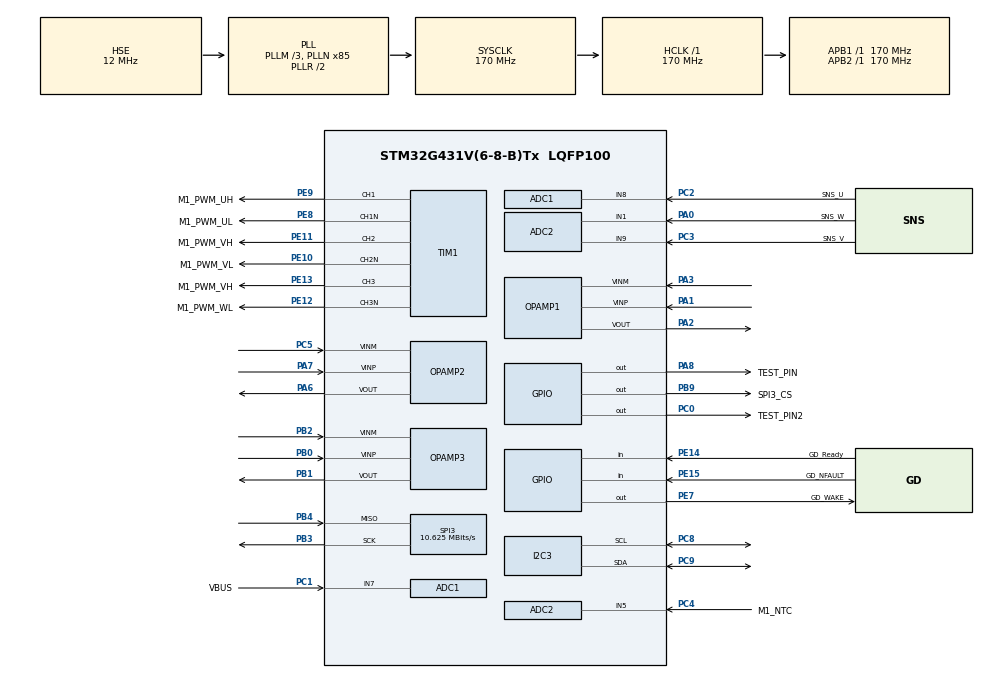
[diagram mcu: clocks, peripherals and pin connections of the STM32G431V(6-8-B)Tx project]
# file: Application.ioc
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ADC1.ClockPrescaler=ADC_CLOCK_ASYNC_DIV4
ADC1.EOCSelection=ADC_EOC_SEQ_CONV
ADC1.EnableInjectedConversion=ENABLE
ADC1.EnableRegularConversion=DISABLE
ADC1.ExternalTrigInjecConv=ADC_EXTERNALTRIGINJEC_T1_TRGO
ADC1.InjNumberOfConversion=4
ADC1.InjectedChannel-1\#ChannelInjectedConversion=ADC_CHANNEL_3
ADC1.InjectedChannel-2\#ChannelInjectedConversion=ADC_CHANNEL_7
ADC1.InjectedChannel-3\#ChannelInjectedConversion=ADC_CHANNEL_12
ADC1.InjectedChannel-4\#ChannelInjectedConversion=ADC_CHANNEL_8
ADC1.InjectedOffsetNumber-1\#ChannelInjectedConversion=ADC_OFFSET_NONE
ADC1.InjectedOffsetNumber-2\#ChannelInjectedConversion=ADC_OFFSET_NONE
ADC1.InjectedOffsetNumber-3\#ChannelInjectedConversion=ADC_OFFSET_NONE
ADC1.InjectedOffsetNumber-4\#ChannelInjectedConversion=ADC_OFFSET_NONE
ADC1.InjectedRank-1\#ChannelInjectedConversion=1
ADC1.InjectedRank-2\#ChannelInjectedConversion=2
ADC1.InjectedRank-3\#ChannelInjectedConversion=3
ADC1.InjectedRank-4\#ChannelInjectedConversion=4
ADC1.InjectedSamplingTime-1\#ChannelInjectedConversion=ADC_SAMPLETIME_6CYCLES_5
ADC1.InjectedSamplingTime-2\#ChannelInjectedConversion=ADC_SAMPLETIME_24CYCLES_5
ADC1.InjectedSamplingTime-3\#ChannelInjectedConversion=ADC_SAMPLETIME_24CYCLES_5
ADC1.InjectedSamplingTime-4\#ChannelInjectedConversion=ADC_SAMPLETIME_24CYCLES_5
ADC1.Rank1_Channel=ADC_CHANNEL_3
ADC1.Rank2_Channel=ADC_CHANNEL_7
ADC1.Rank3_Channel=ADC_CHANNEL_12
ADC1.Rank4_Channel=ADC_CHANNEL_8
ADC1.master=1
ADC2.ClockPrescaler=ADC_CLOCK_ASYNC_DIV4
ADC2.EOCSelection=ADC_EOC_SEQ_CONV
ADC2.EnableInjectedConversion=ENABLE
ADC2.EnableRegularConversion=DISABLE
ADC2.ExternalTrigInjecConv=ADC_EXTERNALTRIGINJEC_T1_TRGO
ADC2.InjNumberOfConversion=4
ADC2.InjectedChannel-1\#ChannelInjectedConversion=ADC_CHANNEL_3
ADC2.InjectedChannel-2\#ChannelInjectedConversion=ADC_CHANNEL_1
ADC2.InjectedChannel-3\#ChannelInjectedConversion=ADC_CHANNEL_5
ADC2.InjectedChannel-4\#ChannelInjectedConversion=ADC_CHANNEL_9
ADC2.InjectedOffsetNumber-1\#ChannelInjectedConversion=ADC_OFFSET_NONE
ADC2.InjectedOffsetNumber-2\#ChannelInjectedConversion=ADC_OFFSET_NONE
ADC2.InjectedOffsetNumber-3\#ChannelInjectedConversion=ADC_OFFSET_NONE
ADC2.InjectedOffsetNumber-4\#ChannelInjectedConversion=ADC_OFFSET_NONE
ADC2.InjectedRank-1\#ChannelInjectedConversion=1
ADC2.InjectedRank-2\#ChannelInjectedConversion=2
ADC2.InjectedRank-3\#ChannelInjectedConversion=3
ADC2.InjectedRank-4\#ChannelInjectedConversion=4
ADC2.InjectedSamplingTime-1\#ChannelInjectedConversion=ADC_SAMPLETIME_6CYCLES_5
ADC2.InjectedSamplingTime-2\#ChannelInjectedConversion=ADC_SAMPLETIME_24CYCLES_5
ADC2.InjectedSamplingTime-3\#ChannelInjectedConversion=ADC_SAMPLETIME_24CYCLES_5
ADC2.InjectedSamplingTime-4\#ChannelInjectedConversion=ADC_SAMPLETIME_24CYCLES_5
ADC2.Rank1_Channel=ADC_CHANNEL_3
ADC2.Rank2_Channel=ADC_CHANNEL_1
ADC2.Rank3_Channel=ADC_CHANNEL_5
ADC2.Rank4_Channel=ADC_CHANNEL_9
FREERTOS.Tasks01=DebugTask,0,128,App_DebugTask,As weak,NULL,Dynamic,NULL,NULL
I2C3.I2C_Fall_Time=100
I2C3.I2C_Rise_Time=100
I2C3.Timing=0x40B285C2
Mcu.Family=STM32G4
Mcu.Name=STM32G431V(6-8-B)Tx
Mcu.Package=LQFP100
Mcu.UserConstants=PWM_PERIOD_CYCLES,8500;TIM_CLOCK_DIVIDER,1;REP_COUNTER,1;DEAD_TIME_COUNTS,170
NVIC.ADC1_2_IRQn=true\:5\:0\:false\:true\:true\:2\:true\:true\:true\:true
NVIC.PriorityGroup=NVIC_PRIORITYGROUP_4
NVIC.TIM1_UP_TIM16_IRQn=true\:5\:0\:false\:true\:true\:1\:true\:true\:true\:true
NVIC.TIM2_IRQn=true\:15\:0\:false\:false\:true\:false\:false\:true\:true
NVIC.TimeBase=TIM2_IRQn
NVIC.TimeBaseIP=TIM2
PA0.GPIO_Label=SNS_W
PA0.Mode=IN1-Single-Ended
PA0.Signal=ADC2_IN1
PA1.Mode=Standalone
PA1.Signal=OPAMP1_VINP
PA13.Mode=Serial_Wire
PA13.Signal=SYS_JTMS-SWDIO
PA14.Mode=Serial_Wire
PA14.Signal=SYS_JTCK-SWCLK
PA2.Signal=SharedAnalog_PA2
PA3.Mode=Standalone
PA3.Signal=OPAMP1_VINM
PA6.Signal=SharedAnalog_PA6
PA7.Mode=Standalone
PA7.Signal=OPAMP2_VINP
PA8.GPIO_Label=TEST_PIN
PA8.GPIO_Speed=GPIO_SPEED_FREQ_VERY_HIGH
PA8.Signal=GPIO_Output
PB0.Mode=Standalone
PB0.Signal=OPAMP3_VINP
PB1.Signal=SharedAnalog_PB1
PB2.Mode=Standalone
PB2.Signal=OPAMP3_VINM
PB3.GPIO_Speed=GPIO_SPEED_FREQ_VERY_HIGH
PB3.Mode=RX_Only_Simplex_Unidirect_Master
PB3.Signal=SPI3_SCK
PB4.GPIO_Speed=GPIO_SPEED_FREQ_VERY_HIGH
PB4.Mode=RX_Only_Simplex_Unidirect_Master
PB4.Signal=SPI3_MISO
PB5.Signal=SPI3_MOSI
PB9.GPIO_FM9=SYSCFG_FASTMODEPLUS_PB9
PB9.GPIO_Label=SPI3_CS
PB9.GPIO_PuPd=GPIO_PULLUP
PB9.GPIO_Speed=GPIO_SPEED_FREQ_VERY_HIGH
PB9.PinState=GPIO_PIN_SET
PB9.Signal=GPIO_Output
PC0.GPIO_Label=TEST_PIN2
PC0.GPIO_Speed=GPIO_SPEED_FREQ_VERY_HIGH
PC0.Signal=GPIO_Output
PC1.GPIO_Label=VBUS
PC1.Mode=IN7-Single-Ended
PC1.Signal=ADC1_IN7
PC2.GPIO_Label=SNS_U
PC2.Mode=IN8-Single-Ended
PC2.Signal=ADC1_IN8
PC3.GPIO_Label=SNS_V
PC3.Mode=IN9-Single-Ended
PC3.Signal=ADC2_IN9
PC4.GPIO_Label=M1_NTC
PC4.Mode=IN5-Single-Ended
PC4.Signal=ADC2_IN5
PC5.Mode=Standalone
PC5.Signal=OPAMP2_VINM
PC8.Mode=I2C
PC8.Signal=I2C3_SCL
PC9.Mode=I2C
PC9.Signal=I2C3_SDA
PE10.GPIO_Label=M1_PWM_VL
PE10.GPIO_PuPd=GPIO_PULLDOWN
PE10.GPIO_Speed=GPIO_SPEED_FREQ_HIGH
PE10.Mode=PWM Generation2 CH2 CH2N
PE10.Signal=TIM1_CH2N
PE11.GPIO_Label=M1_PWM_VH
PE11.GPIO_PuPd=GPIO_PULLDOWN
PE11.GPIO_Speed=GPIO_SPEED_FREQ_HIGH
PE11.Signal=S_TIM1_CH2
PE12.GPIO_Label=M1_PWM_WL
PE12.GPIO_PuPd=GPIO_PULLDOWN
PE12.GPIO_Speed=GPIO_SPEED_FREQ_HIGH
PE12.Mode=PWM Generation3 CH3 CH3N
PE12.Signal=TIM1_CH3N
PE13.GPIO_Label=M1_PWM_VH
PE13.GPIO_PuPd=GPIO_PULLDOWN
PE13.GPIO_Speed=GPIO_SPEED_FREQ_HIGH
PE13.Signal=S_TIM1_CH3
PE14.GPIO_Label=GD_Ready
PE14.Signal=GPIO_Input
PE15.GPIO_Label=GD_NFAULT
PE15.Signal=GPIO_Input
PE7.GPIO_Label=GD_WAKE
PE7.Signal=GPIO_Output
PE8.GPIO_Label=M1_PWM_UL
PE8.GPIO_PuPd=GPIO_PULLDOWN
PE8.GPIO_Speed=GPIO_SPEED_FREQ_HIGH
PE8.Mode=PWM Generation1 CH1 CH1N
PE8.Signal=TIM1_CH1N
PE9.GPIO_Label=M1_PWM_UH
PE9.GPIO_PuPd=GPIO_PULLDOWN
PE9.GPIO_Speed=GPIO_SPEED_FREQ_HIGH
PE9.Signal=S_TIM1_CH1
PF0-OSC_IN.Mode=HSE-External-Oscillator
PF0-OSC_IN.Signal=RCC_OSC_IN
PF1-OSC_OUT.Mode=HSE-External-Oscillator
PF1-OSC_OUT.Signal=RCC_OSC_OUT
ProjectManager.HeapSize=0x200
ProjectManager.StackSize=0x400
ProjectManager.TargetToolchain=CMake
RCC.ADC12Freq_Value=170000000
RCC.AHBFreq_Value=170000000
RCC.APB1Freq_Value=170000000
RCC.APB1TimFreq_Value=170000000
RCC.APB2Freq_Value=170000000
RCC.APB2TimFreq_Value=170000000
RCC.CortexFreq_Value=170000000
RCC.EXTERNAL_CLOCK_VALUE=12288000
RCC.HCLKFreq_Value=170000000
RCC.HSE_VALUE=12000000
RCC.HSI48_VALUE=48000000
RCC.HSI_VALUE=16000000
RCC.LSE_VALUE=32768
RCC.PLLM=RCC_PLLM_DIV3
RCC.PLLN=85
RCC.PLLSourceVirtual=RCC_PLLSOURCE_HSE
RCC.SYSCLKFreq_VALUE=170000000
RCC.SYSCLKSource=RCC_SYSCLKSOURCE_PLLCLK
RCC.USBFreq_Value=170000000
RCC.VCOOutputFreq_Value=340000000
SH.S_TIM1_CH1.0=TIM1_CH1,PWM Generation1 CH1 CH1N
SH.S_TIM1_CH2.0=TIM1_CH2,PWM Generation2 CH2 CH2N
SH.S_TIM1_CH3.0=TIM1_CH3,PWM Generation3 CH3 CH3N
SH.SharedAnalog_PA2.0=OPAMP1_VOUT,Standalone
SH.SharedAnalog_PA2.1=ADC1_IN3,IN3-Single-Ended
SH.SharedAnalog_PA6.0=OPAMP2_VOUT,Standalone
SH.SharedAnalog_PA6.1=ADC2_IN3,IN3-Single-Ended
SH.SharedAnalog_PB1.0=OPAMP3_VOUT,Standalone
SH.SharedAnalog_PB1.1=ADC1_IN12,IN12-Single-Ended
SPI3.BaudRatePrescaler=SPI_BAUDRATEPRESCALER_16
SPI3.CLKPhase=SPI_PHASE_2EDGE
SPI3.CalculateBaudRate=10.625 MBits/s
SPI3.DataSize=SPI_DATASIZE_8BIT
SPI3.Direction=SPI_DIRECTION_2LINES_RXONLY
SPI3.Mode=SPI_MODE_MASTER
SPI3.VirtualType=VM_MASTER
TIM1.Channel-PWM\ Generation1\ CH1\ CH1N=TIM_CHANNEL_1
TIM1.Channel-PWM\ Generation2\ CH2\ CH2N=TIM_CHANNEL_2
TIM1.Channel-PWM\ Generation3\ CH3\ CH3N=TIM_CHANNEL_3
TIM1.Channel-PWM\ Generation4\ No\ Output=TIM_CHANNEL_4
TIM1.ClockDivision=TIM_CLOCKDIVISION_DIV2
TIM1.CounterMode=TIM_COUNTERMODE_CENTERALIGNED1
TIM1.DeadTime=((DEAD_TIME_COUNTS) / 2)
TIM1.OCFastMode_PWM-PWM\ Generation3\ CH3\ CH3N=TIM_OCFAST_DISABLE
TIM1.OCFastMode_PWM-PWM\ Generation4\ No\ Output=TIM_OCFAST_ENABLE
TIM1.OCMode_PWM-PWM\ Generation1\ CH1\ CH1N=TIM_OCMODE_PWM2
TIM1.OCMode_PWM-PWM\ Generation2\ CH2\ CH2N=TIM_OCMODE_PWM2
TIM1.OCMode_PWM-PWM\ Generation3\ CH3\ CH3N=TIM_OCMODE_PWM2
TIM1.OffStateIDLEMode=TIM_OSSI_ENABLE
TIM1.OffStateRunMode=TIM_OSSR_ENABLE
TIM1.PeriodNoDither=((PWM_PERIOD_CYCLES)/2)
TIM1.Prescaler=((TIM_CLOCK_DIVIDER) - 1)
TIM1.PulseNoDither_4=1
TIM1.RepetitionCounter=REP_COUNTER
TIM1.TIM_MasterOutputTrigger=TIM_TRGO_OC4REF
VP_FREERTOS_VS_CMSIS_V1.Mode=CMSIS_V1
VP_SYS_VS_DBSignals.Mode=DisableDeadBatterySignals
VP_SYS_VS_tim2.Mode=TIM2
VP_SYS_V_VREFBUF.Mode=ExternalMode
VP_TIM1_VS_ClockSourceINT.Mode=Internal
VP_TIM1_VS_no_output4.Mode=PWM Generation4 No Output
board=custom

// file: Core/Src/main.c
/* USER CODE BEGIN Header */
/**
  ******************************************************************************
  * @file           : main.c
  * @brief          : Main program body
  ******************************************************************************
  * @attention
  *
  * Copyright (c) 2026 STMicroelectronics.
  * All rights reserved.
  *
  * This software is licensed under terms that can be found in the LICENSE file
  * in the root directory of this software component.
  * If no LICENSE file comes with this software, it is provided AS-IS.
  *
  ******************************************************************************
  */
/* USER CODE END Header */
#include "main.h"
#include "cmsis_os.h"
#include "adc.h"
#include "i2c.h"
#include "opamp.h"
#include "spi.h"
#include "tim.h"
#include "gpio.h"

/* USER CODE BEGIN Includes */
#include "Bsp_Init.h"
#include "Application.h"
/* USER CODE END Includes */

void SystemClock_Config(void);
void MX_FREERTOS_Init(void);
static void MX_NVIC_Init(void);

int main(void)
{

  /* MCU Configuration--------------------------------------------------------*/

  /* Reset of all peripherals, Initializes the Flash interface and the Systick. */
  HAL_Init();

  /* Configure the system clock */
  SystemClock_Config();

  /* Initialize all configured peripherals */
  MX_GPIO_Init();
  MX_ADC1_Init();
  MX_ADC2_Init();
  MX_I2C3_Init();
  MX_OPAMP1_Init();
  MX_OPAMP2_Init();
  MX_OPAMP3_Init();
  MX_SPI3_Init();
  MX_TIM1_Init();

  /* Initialize interrupts */
  MX_NVIC_Init();
  /* USER CODE BEGIN 2 */
  Bsp_Init();
  /* USER CODE END 2 */

  /* Call init function for freertos objects (in cmsis_os2.c) */
  MX_FREERTOS_Init();

  /* Start scheduler */
  osKernelStart();

  /* We should never get here as control is now taken by the scheduler */

  /* Infinite loop */
  while (1)
  {

  }
}

void SystemClock_Config(void)
{
  RCC_OscInitTypeDef RCC_OscInitStruct = {0};
  RCC_ClkInitTypeDef RCC_ClkInitStruct = {0};

  /** Configure the main internal regulator output voltage
  */
  HAL_PWREx_ControlVoltageScaling(PWR_REGULATOR_VOLTAGE_SCALE1_BOOST);

  /** Initializes the RCC Oscillators according to the specified parameters
  * in the RCC_OscInitTypeDef structure.
  */
  RCC_OscInitStruct.OscillatorType = RCC_OSCILLATORTYPE_HSE;
  RCC_OscInitStruct.HSEState = RCC_HSE_ON;
  RCC_OscInitStruct.PLL.PLLState = RCC_PLL_ON;
  RCC_OscInitStruct.PLL.PLLSource = RCC_PLLSOURCE_HSE;
  RCC_OscInitStruct.PLL.PLLM = RCC_PLLM_DIV3;
  RCC_OscInitStruct.PLL.PLLN = 85;
  RCC_OscInitStruct.PLL.PLLP = RCC_PLLP_DIV2;
  RCC_OscInitStruct.PLL.PLLQ = RCC_PLLQ_DIV2;
  RCC_OscInitStruct.PLL.PLLR = RCC_PLLR_DIV2;
  if (HAL_RCC_OscConfig(&RCC_OscInitStruct) != HAL_OK)
  {
    Error_Handler();
  }

  /** Initializes the CPU, AHB and APB buses clocks
  */
  RCC_ClkInitStruct.ClockType = RCC_CLOCKTYPE_HCLK|RCC_CLOCKTYPE_SYSCLK
                              |RCC_CLOCKTYPE_PCLK1|RCC_CLOCKTYPE_PCLK2;
  RCC_ClkInitStruct.SYSCLKSource = RCC_SYSCLKSOURCE_PLLCLK;
  RCC_ClkInitStruct.AHBCLKDivider = RCC_SYSCLK_DIV1;
  RCC_ClkInitStruct.APB1CLKDivider = RCC_HCLK_DIV1;
  RCC_ClkInitStruct.APB2CLKDivider = RCC_HCLK_DIV1;

  if (HAL_RCC_ClockConfig(&RCC_ClkInitStruct, FLASH_LATENCY_4) != HAL_OK)
  {
    Error_Handler();
  }
}

/**
  * @brief NVIC Configuration.
  * @retval None
  */
static void MX_NVIC_Init(void)
{
  /* TIM1_UP_TIM16_IRQn interrupt configuration */
  HAL_NVIC_SetPriority(TIM1_UP_TIM16_IRQn, 5, 0);
  HAL_NVIC_EnableIRQ(TIM1_UP_TIM16_IRQn);
  /* ADC1_2_IRQn interrupt configuration */
  HAL_NVIC_SetPriority(ADC1_2_IRQn, 5, 0);
  HAL_NVIC_EnableIRQ(ADC1_2_IRQn);
}

void HAL_TIM_PeriodElapsedCallback(TIM_HandleTypeDef *htim)
{
  if (htim->Instance == TIM2)
  {
    HAL_IncTick();
  }
}

void Error_Handler(void)
{
  __disable_irq();
  while (1)
  {
  }
}

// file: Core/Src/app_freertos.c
/* USER CODE BEGIN Header */
/**
  ******************************************************************************
  * File Name          : app_freertos.c
  * Description        : Code for freertos applications
  ******************************************************************************
  * @attention
  *
  * Copyright (c) 2026 STMicroelectronics.
  * All rights reserved.
  *
  * This software is licensed under terms that can be found in the LICENSE file
  * in the root directory of this software component.
  * If no LICENSE file comes with this software, it is provided AS-IS.
  *
  ******************************************************************************
  */
/* USER CODE END Header */

#include "FreeRTOS.h"
#include "task.h"
#include "main.h"
#include "cmsis_os.h"

osThreadId DebugTaskHandle;

void App_DebugTask(void const * argument);

void MX_FREERTOS_Init(void); /* (MISRA C 2004 rule 8.1) */

void MX_FREERTOS_Init(void) {

  /* Create the thread(s) */
  /* definition and creation of DebugTask */
  osThreadDef(DebugTask, App_DebugTask, osPriorityNormal, 0, 128);
  DebugTaskHandle = osThreadCreate(osThread(DebugTask), NULL);

}

__weak void App_DebugTask(void const * argument)
{
  for(;;)
  {
    osDelay(1);
  }
}
